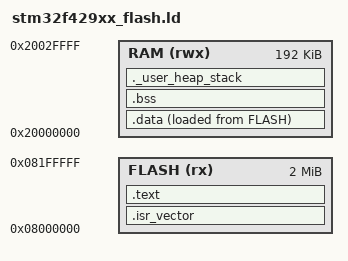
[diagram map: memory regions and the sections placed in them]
/* Minimal linker script for STM32F429xx.
 *   FLASH : 2 MB @ 0x08000000
 *   RAM   : 192 KB @ 0x20000000  (stack top at 0x20030000) */

ENTRY(Reset_Handler)

_estack = 0x20030000;

MEMORY
{
  FLASH (rx)  : ORIGIN = 0x08000000, LENGTH = 2048K
  RAM   (rwx) : ORIGIN = 0x20000000, LENGTH = 192K
}

SECTIONS
{
  .isr_vector :
  {
    . = ALIGN(4);
    KEEP(*(.isr_vector))
    . = ALIGN(4);
  } > FLASH

  .text :
  {
    *(.text*)
    *(.rodata*)
    . = ALIGN(4);
  } > FLASH

  _sidata = LOADADDR(.data);

  .data :
  {
    . = ALIGN(4);
    _sdata = .;
    *(.data*)
    . = ALIGN(4);
    _edata = .;
  } > RAM AT > FLASH

  .bss :
  {
    . = ALIGN(4);
    _sbss = .;
    *(.bss*)
    *(COMMON)
    . = ALIGN(4);
    _ebss = .;
  } > RAM

  ._user_heap_stack :
  {
    . = ALIGN(8);
    . = . + 0x400;
    . = ALIGN(8);
  } > RAM
}
